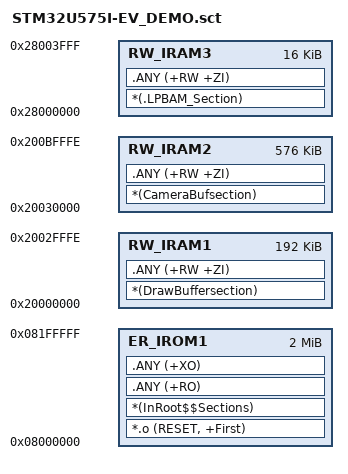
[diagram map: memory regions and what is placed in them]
; *************************************************************
; *** Scatter-Loading Description File generated by uVision ***
; *************************************************************

LR_IROM1 0x08000000 0x00200000  {    ; load region size_region
  ER_IROM1 0x08000000 0x00200000  {  ; load address = execution address
   *.o (RESET, +First)
   *(InRoot$$Sections)
   .ANY (+RO)
   .ANY (+XO)
  }
  RW_IRAM1 0x20000000 0x2FFFF  {  ; RW data
    *(DrawBuffersection)
   .ANY (+RW +ZI)
  }
    RW_IRAM2 0x20030000 0x8FFFF  {  ; RW data
    *(CameraBufsection)
   .ANY (+RW +ZI)
  }
  
  RW_IRAM3 0x28000000 0x00004000  {
    *(.LPBAM_Section)
   .ANY (+RW +ZI)
  }
}

